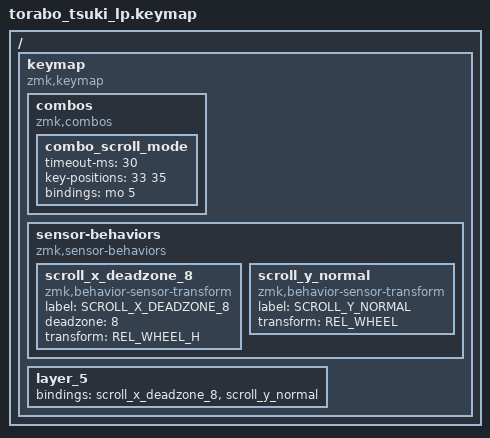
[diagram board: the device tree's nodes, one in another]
/ {
    keymap {
        compatible = "zmk,keymap";

        /* ----------------------------------
         * JL コンボ → レイヤー5に切り替え
         * （スクロールモード）
         * ---------------------------------- */
        combos {
            compatible = "zmk,combos";

            combo_scroll_mode {
                timeout-ms = <30>;
                key-positions = <33 35>;
                bindings = <&mo 5>;
            };
        };

        /* ----------------------------------
         * スクロールモード用センサー処理
         * 横移動 8 以下は無視（デッドゾーン）
         * ---------------------------------- */
        sensor-behaviors {
            compatible = "zmk,sensor-behaviors";

            /* 横スクロール（X方向）フィルタ済み */
            scroll_x_deadzone_8 {
                compatible = "zmk,behavior-sensor-transform";
                label = "SCROLL_X_DEADZONE_8";

                /* 絶対値8以下は0扱い → デッドゾーン */
                deadzone = <8>;

                /* ここはホイールに変換する */
                transform = "REL_WHEEL_H";
            };

            /* 縦スクロールは通常のまま */
            scroll_y_normal {
                compatible = "zmk,behavior-sensor-transform";
                label = "SCROLL_Y_NORMAL";
                transform = "REL_WHEEL";
            };
        };

        /* ----------------------------------
         * レイヤー5（スクロールモード）
         * ↑モード中にだけデッドゾーン動作
         * ---------------------------------- */
        layer_5 {
            bindings = <
                &scroll_x_deadzone_8
                &scroll_y_normal
            >;
        };
    };
};

/* 元のキーマップを取り込む */
#include "../../../config/keymap.keymap"
